# ExynosT100 register map
Vendor: SAMSUNG System LSI; Series: ARMCM4F; File version: 0.1
CPU: CM4 r1p0, little endian, MPU, FPU, 3 interrupt priority bits
Registers are 32-bit, read-write, reset 0x0 unless marked. A register's access mark holds for its fields unless they carry their own. Offsets are from the block's base; [hi:lo] are bit positions; {n}, {i} and the like mark numbered series.

## PMU — Power Management
Base 0x40080800
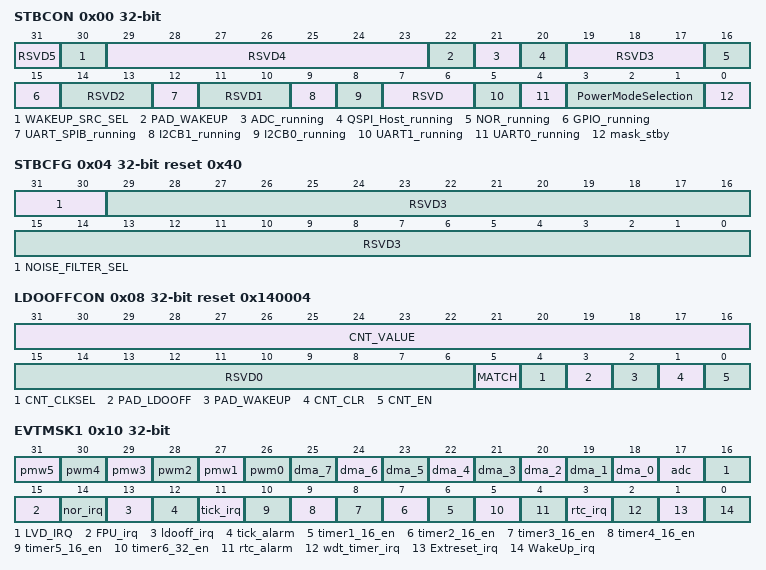
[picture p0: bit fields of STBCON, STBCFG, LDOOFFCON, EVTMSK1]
0x00 STBCON — Power Saving Mode Control Register
  [31] RSVD5 ro
  [30] WAKEUP_SRC_SEL — Wake-up source selection 0 = Interface wake-up (Wakeup pad, I2C, SPI, UART, GPIO, and warm reset) 1 = Wake-up pad only
  [29:23] RSVD4 ro
  [22] PAD_WAKEUP — Wake-up running (value is differ as WAKEUP PAD) 0 = Wake-up is high (in reading) 1 = Clears running state of wake-up (in writing) 1 = Wake-up (is low) is in running state
  [21] ADC_running — ADC running 0 = Interface is idle (in reading) 1 = Clear running state of NOR interface (in writing) 1 = Interface is in running state
  [20] QSPI_Host_running — QSPI host running 0 = Interface is idle (in reading) 1 = Clear running state of NOR interface (in writing) 1 = NOR interface is in running state
  [19:17] RSVD3 ro
  [16] NOR_running — NOR running 0 = NOR interface is idle (in reading) 1 = Clear running state of GPIO interface (in writing) 1 = GPIO interface is in running state
  [15] GPIO_running — GPIO running 0 = GPIO interface is idle (in reading) 1 = Clear running state of SPI master interface (in writing) 1 = SPI Master interface is in running state
  [14:13] RSVD2 ro
  [12] UART_SPIB_running — UART or SPI both running 0 = UART or SPI both interface is idle (in reading) 1 = Clear running state of I2C master1 interface (in writing) 1 = I2C master1 interface is in running state
  [11:10] RSVD1 ro
  [9] I2CB1_running — I2C both1 running 0 = I2C master1 interface is idle (in reading) 1 = Clear running state of I2C master0 interface (in writing) 1 = I2C master0 interface is in running state
  [8] I2CB0_running — I2C both0 running 0 = I2C master0 interface is idle (in reading) 1 = Clear running state of I2C master0 interface (in writing) 1 = I2C master0 interface is in running state
  [7:6] RSVD ro
  [5] UART1_running — UART1 running 0 = UART1 interface is idle (in reading) 1 = Clear running state of UART1 interface (in writing) 1 = UART1 interface is in running state
  [4] UART0_running — UART0 running 0 = UART0 interface is idle (in reading) 1 = Clear running state of UART0 interface (in writing) 1 = UART0 interface is in running state
  [3:1] PowerModeSelection — 000 = Sleep all retention mode 001 = Sleep RAM retention mode 010 = Deep sleep 100 = Ultra deep sleep Others = Active
  [0] mask_stby — 0 = Standby masking off 1 = Standby masking on (standby disable)
0x04 STBCFG reset 0x40 — IDLE/Sleep All Retention Mode Configuration Register
  [31:30] NOISE_FILTER_SEL — 00 = 1ns noise filter 01 = 2ns noise filter 10 = 3ns noise filter 11 = 4ns noise filter
  [29:0] RSVD3 ro
0x08 LDOOFFCON reset 0x140004 — Sleep RAM Retention/Deep Sleep/Ultra Deep Sleep Mode Control Register
  [31:16] CNT_VALUE — CNT value (0x14 @ 2Mhz)
  [15:6] RSVD0 ro
  [5] MATCH ro — CNT match 0 : standby 1 : match
  [4] CNT_CLKSEL — "CNT clk selection 0: RCOSC 4MHz 1 : system clk"
  [3] PAD_LDOOFF ro — ldooff pad value
  [2] PAD_WAKEUP ro — wakeup pad value / WKL_SYSOSCSTOP@TMODE 0: low 1 : high"
  [1] CNT_CLR — CNT value clear 0 : no effect 1 : clear for CNT, MATCH
  [0] CNT_EN — CNT enable 0: disable 1: enable"
0x0C LDOOFFCNT reset 0x7F — Active LDO Control Register
  [15:0] CNT ro — Count value
0x10 EVTMSK1 — Event Mask Control Register 1
  [31] pmw5, [30] pwm4, [29] pmw3, [28] pwm2, [27] pmw1, [26] pwm0, [n+18] dma_{n} (n=0..7), [17] adc, [16] LVD_IRQ, [15] FPU_irq, [14] nor_irq, [13] ldooff_irq, [12] tick_alarm, [11] tick_irq, [n+5] timer{n}_16_en (n=1..5), [5] timer6_32_en, [4] rtc_alarm, [3] rtc_irq, [2] wdt_timer_irq, [1] Extreset_irq, [0] WakeUp_irq
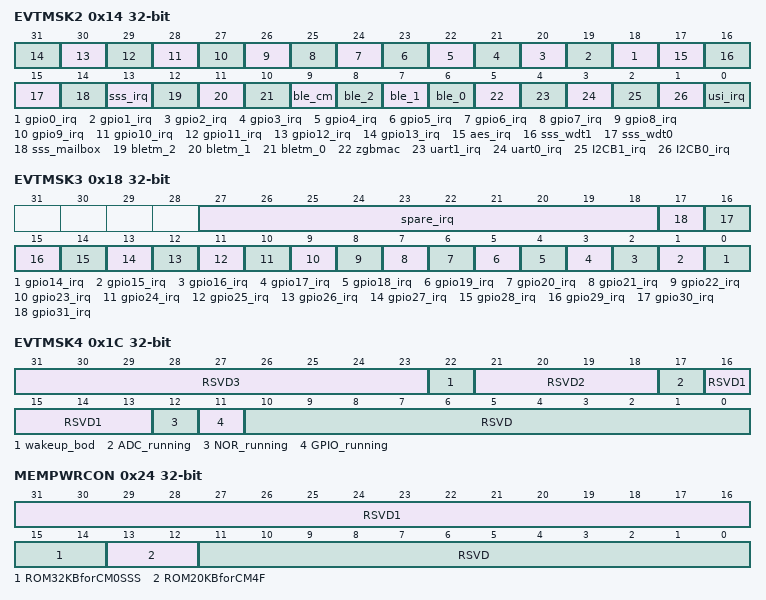
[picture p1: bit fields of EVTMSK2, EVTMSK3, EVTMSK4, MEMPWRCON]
0x14 EVTMSK2 — Event Mask Control Register 2
  [n+18] gpio{n}_irq (n=0..13), [17] aes_irq, [16] sss_wdt1, [15] sss_wdt0, [14] sss_mailbox, [13] sss_irq, [12] bletm_2, [11] bletm_1, [10] bletm_0, [9] ble_cm, [8] ble_2, [7] ble_1, [6] ble_0, [5] zgbmac, [4] uart1_irq, [3] uart0_irq, [2] I2CB1_irq, [1] I2CB0_irq, [0] usi_irq
0x18 EVTMSK3 — Event Mask Control Register 3
  [27:18] spare_irq, [n-14] gpio{n}_irq (n=14..31)
0x1C EVTMSK4 — Event Mask Control Register 4
  [31:23] RSVD3 ro, [22] wakeup_bod, [21:18] RSVD2, [17] ADC_running, [16:13] RSVD1, [12] NOR_running, [11] GPIO_running, [10:0] RSVD ro
0x24 MEMPWRCON — Memory Power Control Register
  [31:16] RSVD1 ro, [15:14] ROM32KBforCM0SSS, [13:12] ROM20KBforCM4F, [11:0] RSVD ro
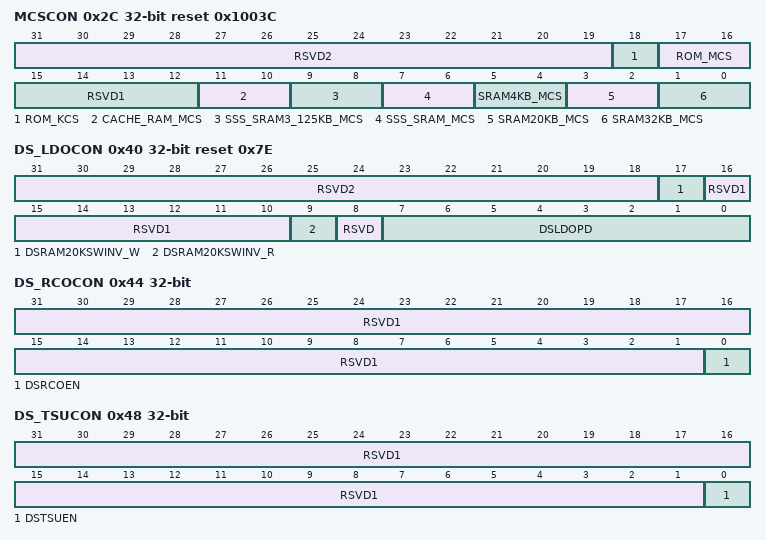
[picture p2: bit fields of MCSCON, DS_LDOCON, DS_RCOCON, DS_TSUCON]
0x2C MCSCON reset 0x1003C — MCS Control Register
  [31:19] RSVD2 ro
  [18] ROM_KCS — CM4F + CM0 ROM KCS
  [17:16] ROM_MCS
  [15:12] RSVD1 ro
  [11:10] CACHE_RAM_MCS
  [9:8] SSS_SRAM3_125KB_MCS
  [7:6] SSS_SRAM_MCS — SSS SRAM 16 KB/3.125 KB MCS
  [5:4] SRAM4KB_MCS — UDS SRAM 4 KB MCS
  [3:2] SRAM20KB_MCS — DS SRAM 20 KB MCS
  [1:0] SRAM32KB_MCS
0x40 DS_LDOCON reset 0x7E — Deep Sleep LDO Control Register
  [31:18] RSVD2 ro
  [17] DSRAM20KSWINV_W wo — DS RAM 20 KB SW_INV from LDO_MEM 0 = Switch enable 1 = Switch disable This is a write-only field. Ignore the read value
  [16:10] RSVD1 ro
  [9] DSRAM20KSWINV_R ro — DS RAM 20 KB SW_INV from LDO_MEM 0 = Switch enable 1 = Switch disable This is a read-only field(status)
  [8] RSVD
  [7:0] DSLDOPD — DS_LDO_ALV power-down (0 = LDO enable, 1 = Power down) [7]: LDO_ALV_PD (default enable) [6]: LDO_ALV_GPADC_PD [5]: LDO_ALV_RAM_PD (default disable) [4]: LDO_ALV_RTC_PD (reserved) [3]: LDO_ALV_TSU_PD [2]: LDO_ALV_TSU_VREF_PD (don't use, can control with [3]) [1]: LDO_ALV_RCO_PD (default disable) [0]: 0 = Don't use this bit LDO_ALV_PMU_PD (default enable) for INT POR ALV
0x44 DS_RCOCON — Deep Sleep RCO Control Register
  [31:1] RSVD1 ro
  [0] DSRCOEN — DS RCO 10 kHz enable 0 = Disable 1 = Enable
0x48 DS_TSUCON — Deep Sleep TSU Control Register
  [31:1] RSVD1 ro
  [0] DSTSUEN — DS TSU enable 0 = Disable 1 = Enable
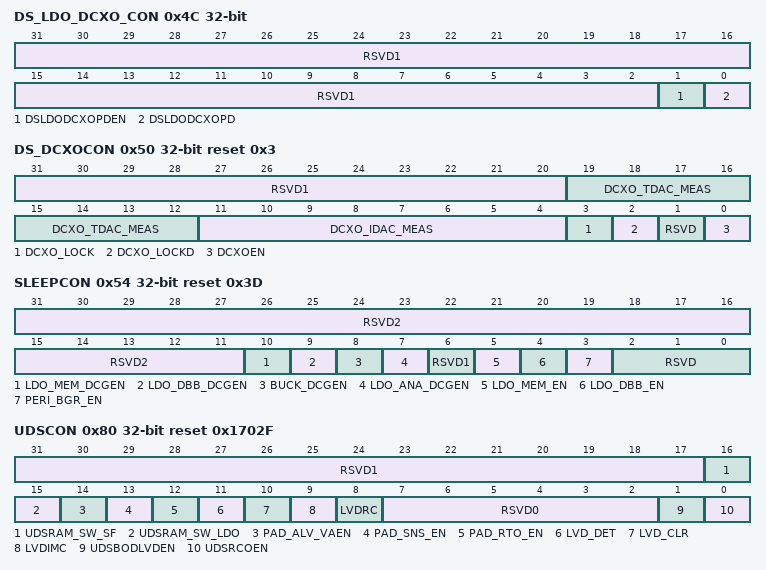
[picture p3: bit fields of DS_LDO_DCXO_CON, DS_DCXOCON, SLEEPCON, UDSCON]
0x4C DS_LDO_DCXO_CON — Deep Sleep LDO_DCXO Control Register
  [31:2] RSVD1
  [1] DSLDODCXOPDEN — DS_LDO_DCXO pull-down enable during discharge 0 = Discharge disable 1 = Discharge enable
  [0] DSLDODCXOPD — DS_LDO_DCXO power-down 0 = LDO enable 1 = LDO power-down
0x50 DS_DCXOCON reset 0x3 — Deep Sleep DCXO Control Register
  [31:20] RSVD1
  [19:12] DCXO_TDAC_MEAS ro — DCXO TDAC_MEAS: time DAC code monitor
  [11:4] DCXO_IDAC_MEAS ro — DCXO IDAC_MEAS: current DAC code monitor
  [3] DCXO_LOCK — DCXO LOCK for RF / ABX block (phase noise: 40 ppm) 0 = No lock 1 = Lock
  [2] DCXO_LOCKD — DCXO LOCKD for digital block (duty 50:50) 0 = No lock 1 = Lock
  [1] RSVD ro
  [0] DCXOEN — DS DCXO enable 0 = Disable 1 = Enable
0x54 SLEEPCON reset 0x3D — Sleep Control Register
  [31:11] RSVD2, [10] LDO_MEM_DCGEN, [9] LDO_DBB_DCGEN, [8] BUCK_DCGEN, [7] LDO_ANA_DCGEN, [6] RSVD1 ro, [5] LDO_MEM_EN, [4] LDO_DBB_EN, [3] PERI_BGR_EN, [2:0] RSVD ro
0x80 UDSCON reset 0x1702F — Ultra Deep Sleep Control Register
  [31:17] RSVD1, [16] UDSRAM_SW_SF, [15] UDSRAM_SW_LDO, [14] PAD_ALV_VAEN, [13] PAD_SNS_EN, [12] PAD_RTO_EN, [11] LVD_DET ro, [10] LVD_CLR, [9] LVDIMC, [8] LVDRC, [7:2] RSVD0, [1] UDSBODLVDEN, [0] UDSRCOEN
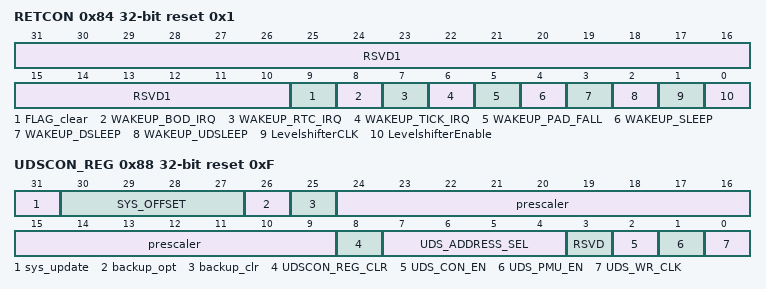
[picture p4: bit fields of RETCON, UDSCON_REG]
0x84 RETCON reset 0x1 — Retention Control Register
  [31:10] RSVD1 ro, [9] FLAG_clear, [8] WAKEUP_BOD_IRQ ro, [7] WAKEUP_RTC_IRQ ro, [6] WAKEUP_TICK_IRQ ro, [5] WAKEUP_PAD_FALL ro, [4] WAKEUP_SLEEP ro, [3] WAKEUP_DSLEEP ro, [2] WAKEUP_UDSLEEP ro, [1] LevelshifterCLK, [0] LevelshifterEnable
0x88 UDSCON_REG reset 0xF — UDS Register Control Register
  [31] sys_update
  [30:27] SYS_OFFSET — System counter update 0 = S/W cannot update system counter 1 = S/W can update system counter
  [26] backup_opt — 0 = Enable 1 = Disable
  [25] backup_clr — Backup_clr (read value shows backup_done or not)
  [24:9] prescaler — Prescaler value for calculation of system counter
  [8] UDSCON_REG_CLR — You must write 1 and 0 for clearing
  [7:4] UDS_ADDRESS_SEL — UDS write address selection (0~15)
  [3] RSVD
  [2] UDS_CON_EN — UDS CON address selection
  [1] UDS_PMU_EN — UDS PMU address selection
  [0] UDS_WR_CLK — UDS register write/read clock
0x8C UDSCON_DATA reset 0xF — UDS Data Control Register
  [31:0] UDSCON_DATA — Data which are written in UDS_CON/PMU register
